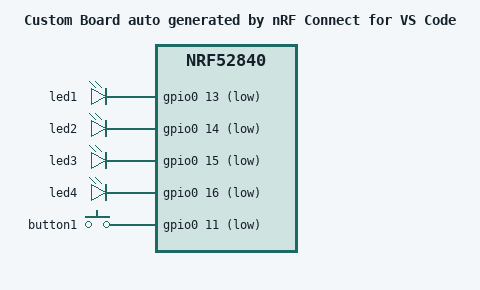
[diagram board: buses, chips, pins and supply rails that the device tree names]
/dts-v1/;
#include <nordic/nrf52840_qiaa.dtsi>
#include "nrf52840dk_custom-pinctrl.dtsi"

/ {
	model = "Custom Board auto generated by nRF Connect for VS Code";
	compatible = "Thyra,nrf52840dk-custom";

	chosen {
		zephyr,sram = &sram0;
		zephyr,flash = &flash0;
		zephyr,code-partition = &slot0_partition;
	};

	leds {
		compatible = "gpio-leds";
		led1: led1 {
			gpios = <&gpio0 13 (GPIO_ACTIVE_LOW)>;
		};
		led2: led2 {
			gpios = <&gpio0 14 (GPIO_ACTIVE_LOW)>;
		};
		led3: led3 {
			gpios = <&gpio0 15 (GPIO_ACTIVE_LOW)>;
		};
		led4: led4 {
			gpios = <&gpio0 16 (GPIO_ACTIVE_LOW)>;
		};
	};

	buttons {
		compatible = "gpio-keys";
		button1: button1 {
			gpios = <&gpio0 11 (GPIO_ACTIVE_LOW | GPIO_PULL_UP)>;
		};
	};

	// LED1 = <&gpio0 13 0>;
	// LED2 = <&gpio0 14 0>;
	// LED3 = <&gpio0 15 0>;
	// LED4 = <&gpio0 16 0>;
	// BUTTON1 = <&gpio0 11 (GPIO_ACTIVE_LOW | GPIO_PULL_UP)>;
	// BUTTON2 = <&gpio0 12 (GPIO_ACTIVE_LOW | GPIO_PULL_UP)>;
	// BUTTON3 = <&gpio0 24 (GPIO_ACTIVE_LOW | GPIO_PULL_UP)>;
	// BUTTON4 = <&gpio0 25 (GPIO_ACTIVE_LOW | GPIO_PULL_UP)>;

};

&flash0 {
	partitions {
		compatible = "fixed-partitions";
		#address-cells = <1>;
		#size-cells = <1>;

		boot_partition: partition@0 {
			label = "mcuboot";
			reg = <0x00000000 DT_SIZE_K(48)>;
		};

		slot0_partition: partition@c000 {
			label = "image-0";
			reg = <0x0000c000 DT_SIZE_K(472)>;
		};

		slot1_partition: partition@82000 {
			label = "image-1";
			reg = <0x00082000 DT_SIZE_K(472)>;
		};

		storage_partition: partition@f8000 {
			label = "storage";
			reg = <0x000f8000 DT_SIZE_K(32)>;
		};
	};
};
&gpio0 {
	status = "okay";
};

&gpio1 {
	status = "okay";
};

&gpiote {
	status = "okay";
};
